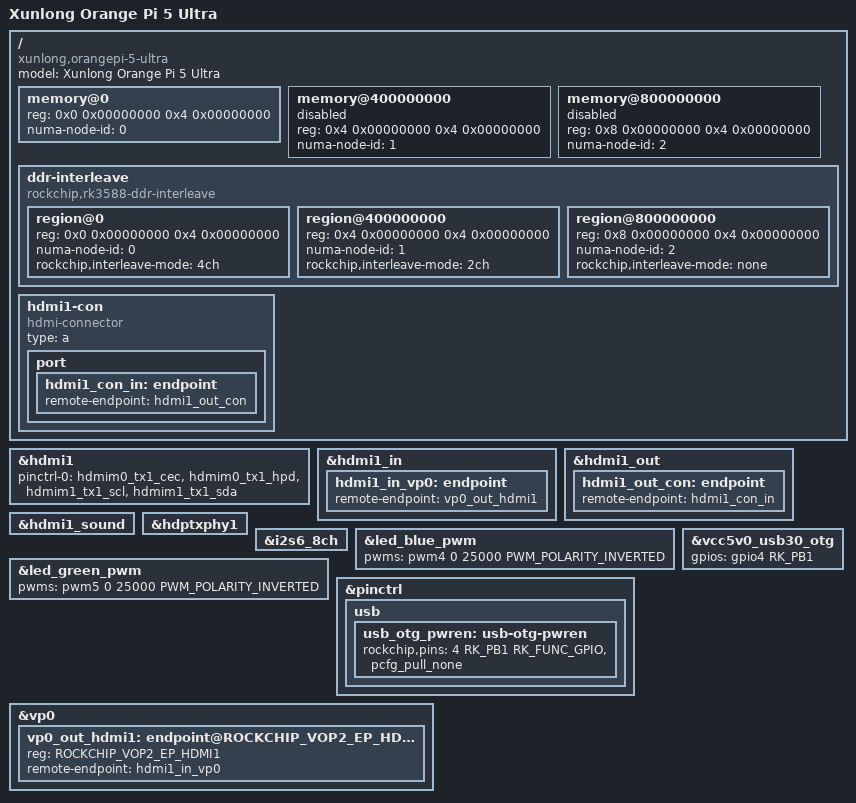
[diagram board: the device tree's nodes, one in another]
// SPDX-License-Identifier: (GPL-2.0+ OR MIT)

/dts-v1/;

#include <dt-bindings/gpio/gpio.h>
#include <dt-bindings/pinctrl/rockchip.h>
#include <dt-bindings/pwm/pwm.h>
#include <dt-bindings/soc/rockchip,vop2.h>
#include "rk3588-orangepi-5-compact.dtsi"

/ {
	model = "Xunlong Orange Pi 5 Ultra";
	compatible = "xunlong,orangepi-5-ultra", "rockchip,rk3588";

	memory@0 {
		device_type = "memory";
		reg = <0x0 0x00000000 0x4 0x00000000>;
		numa-node-id = <0>;
	};

	memory@400000000 {
		device_type = "memory";
		reg = <0x4 0x00000000 0x4 0x00000000>;
		numa-node-id = <1>;
		status = "disabled";
	};

	memory@800000000 {
		device_type = "memory";
		reg = <0x8 0x00000000 0x4 0x00000000>;
		numa-node-id = <2>;
		status = "disabled";
	};

	ddr-interleave {
		compatible = "rockchip,rk3588-ddr-interleave";
		#address-cells = <2>;
		#size-cells = <2>;

		region@0 {
			reg = <0x0 0x00000000 0x4 0x00000000>;
			numa-node-id = <0>;
			rockchip,interleave-mode = "4ch";
		};

		region@400000000 {
			reg = <0x4 0x00000000 0x4 0x00000000>;
			numa-node-id = <1>;
			rockchip,interleave-mode = "2ch";
		};

		region@800000000 {
			reg = <0x8 0x00000000 0x4 0x00000000>;
			numa-node-id = <2>;
			rockchip,interleave-mode = "none";
		};
	};

	hdmi1-con {
		compatible = "hdmi-connector";
		type = "a";

		port {
			hdmi1_con_in: endpoint {
				remote-endpoint = <&hdmi1_out_con>;
			};
		};
	};
};

&hdmi1 {
	pinctrl-names = "default";
	pinctrl-0 = <&hdmim0_tx1_cec &hdmim0_tx1_hpd
			     &hdmim1_tx1_scl &hdmim1_tx1_sda>;
	status = "okay";
};

&hdmi1_in {
	hdmi1_in_vp0: endpoint {
		remote-endpoint = <&vp0_out_hdmi1>;
	};
};

&hdmi1_out {
	hdmi1_out_con: endpoint {
		remote-endpoint = <&hdmi1_con_in>;
	};
};

&hdmi1_sound {
	status = "okay";
};

&hdptxphy1 {
	status = "okay";
};

&i2s6_8ch {
	status = "okay";
};

&led_blue_pwm {
	pwms = <&pwm4 0 25000 PWM_POLARITY_INVERTED>;
};

&led_green_pwm {
	pwms = <&pwm5 0 25000 PWM_POLARITY_INVERTED>;
};

&pinctrl {
	usb {
		usb_otg_pwren: usb-otg-pwren {
			rockchip,pins = <4 RK_PB1 RK_FUNC_GPIO &pcfg_pull_none>;
		};
	};
};

&vcc5v0_usb30_otg {
	gpios = <&gpio4 RK_PB1 GPIO_ACTIVE_HIGH>;
};

&vp0 {
	vp0_out_hdmi1: endpoint@ROCKCHIP_VOP2_EP_HDMI1 {
		reg = <ROCKCHIP_VOP2_EP_HDMI1>;
		remote-endpoint = <&hdmi1_in_vp0>;
	};
};
